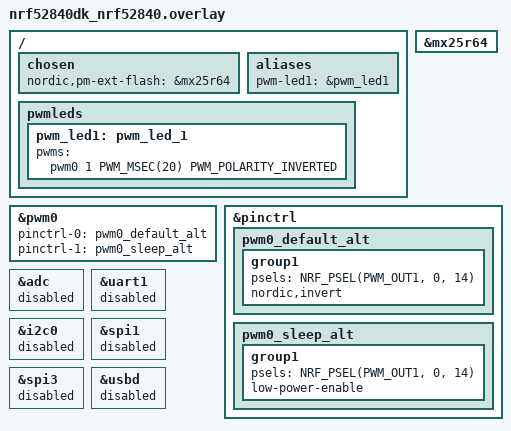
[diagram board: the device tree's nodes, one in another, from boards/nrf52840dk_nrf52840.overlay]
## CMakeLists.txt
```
#
#  Copyright (c) 2025 Nordic Semiconductor ASA
#
#  SPDX-License-Identifier: LicenseRef-Nordic-5-Clause
#


cmake_minimum_required(VERSION 3.20.0)

include(${CMAKE_CURRENT_LIST_DIR}/../../cmake/find_zephyr.cmake)

project(matter-closure)

# NORDIC SDK APP START

# Include all source files that are located in the Matter common directory.
include(${ZEPHYR_NCS_MATTER_MODULE_DIR}/cmake/sample.cmake)

ncs_get_zap_parent_dir(ZAP_PARENT_DIR)

target_include_directories(app PRIVATE
  src
  ${ZEPHYR_NCS_MATTER_MODULE_DIR}/subsys/util
  ${ZAP_PARENT_DIR}
)

target_sources(app PRIVATE
  src/app_task.cpp
  src/main.cpp
  src/closure_manager.cpp
  src/closure_control_endpoint.cpp
  src/garage_door_impl.cpp
  src/persistent_percent.cpp
)

ncs_configure_data_model()
# NORDIC SDK APP END
```

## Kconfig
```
#
# Copyright (c) 2025 Nordic Semiconductor
#
# SPDX-License-Identifier: LicenseRef-Nordic-5-Clause
#
mainmenu "Matter nRF Connect Closure Example Application"

# Sample configuration used for Thread networking
if OPENTHREAD

choice OPENTHREAD_NORDIC_LIBRARY_CONFIGURATION
	default OPENTHREAD_NORDIC_LIBRARY_FTD
endchoice

choice OPENTHREAD_DEVICE_TYPE
	default OPENTHREAD_FTD
endchoice

choice OPENTHREAD_IMPLEMENTATION
	default OPENTHREAD_SOURCES
endchoice

endif # OPENTHREAD

# Default triggers register OTA handler; this sample adds its own handler.
config MATTER_TEST_EVENT_TRIGGERS_MAX_TRIGGERS_DELEGATES
	default 3

config CHIP_WIFI
	default y if SHIELD_NRF7002EB2

source "$(ZEPHYR_CONNECTEDHOMEIP_MODULE_DIR)/config/nrfconnect/chip-module/Kconfig.features"
source "$(ZEPHYR_CONNECTEDHOMEIP_MODULE_DIR)/config/nrfconnect/chip-module/Kconfig.defaults"
source "Kconfig.zephyr"
```

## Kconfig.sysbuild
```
#
# Copyright (c) 2025 Nordic Semiconductor ASA
#
# SPDX-License-Identifier: LicenseRef-Nordic-5-Clause
#

config MATTER_ADD_ON
	default y

#### Radio core selection
config NRF_DEFAULT_IPC_RADIO
	default y

# Enable IEEE802.15.4 serialization to network core
# This config automatically pulls in the `overlay-802154.conf` in the ipc_radio image
config NETCORE_IPC_RADIO_IEEE802154
	default y if SOC_SERIES_NRF53

# Enable Bluetooth serialization to network core
# This config automatically pulls in the `overlay-bt_hci_ipc.conf` in the ipc_radio image
config NETCORE_IPC_RADIO_BT_HCI_IPC
	default y if SOC_SERIES_NRF53

#### Matter OTA
config MATTER_ADD_ON_OTA
	default n if BOARD_NRF7120DK_NRF7120_CPUAPP

#### Bootloader
choice BOOTLOADER
	default BOOTLOADER_MCUBOOT if !BOARD_NRF7120DK_NRF7120_CPUAPP
endchoice

if BOOTLOADER_MCUBOOT

#### DFU multi-image support
config DFU_MULTI_IMAGE_PACKAGE_BUILD
	default y

config DFU_MULTI_IMAGE_PACKAGE_APP
	default y

#### DFU network core configuration
if SOC_SERIES_NRF53

choice MCUBOOT_MODE
	default MCUBOOT_MODE_OVERWRITE_ONLY
endchoice

choice BOOT_SIGNATURE_TYPE
	default BOOT_SIGNATURE_TYPE_RSA
endchoice

config SECURE_BOOT_NETCORE
	default y

config NETCORE_APP_UPDATE
	default y

config DFU_MULTI_IMAGE_PACKAGE_NET
	default y

endif # SOC_SERIES_NRF53
endif # BOOTLOADER_MCUBOOT

#### Enable generating factory data
config MATTER_ADD_ON_FACTORY_DATA_GENERATE
	default y

source "share/sysbuild/Kconfig"
```

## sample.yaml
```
sample:
  description: Matter Closure sample
  name: Matter Closure
common:
  tags:
    - sysbuild
    - ci_samples_matter
tests:
  sample.matter.closure.debug:
    sysbuild: true
    build_only: true
    integration_platforms:
      - nrf5340dk/nrf5340/cpuapp
      - nrf54l15dk/nrf54l15/cpuapp
      - nrf54lm20dk/nrf54lm20b/cpuapp
      - nrf54lm20dk/nrf54lm20a/cpuapp
    platform_allow:
      - nrf5340dk/nrf5340/cpuapp
      - nrf54l15dk/nrf54l15/cpuapp
      - nrf54lm20dk/nrf54lm20b/cpuapp
      - nrf54lm20dk/nrf54lm20a/cpuapp
  sample.matter.closure.release:
    sysbuild: true
    build_only: true
    extra_args:
      - FILE_SUFFIX=release
    integration_platforms:
      - nrf5340dk/nrf5340/cpuapp
      - nrf54l15dk/nrf54l15/cpuapp
      - nrf54lm20dk/nrf54lm20b/cpuapp
      - nrf54lm20dk/nrf54lm20a/cpuapp
    platform_allow:
      - nrf5340dk/nrf5340/cpuapp
      - nrf54l15dk/nrf54l15/cpuapp
      - nrf54lm20dk/nrf54lm20b/cpuapp
      - nrf54lm20dk/nrf54lm20a/cpuapp
  sample.matter.closure.nrf7002eb2.debug:
    sysbuild: true
    build_only: true
    extra_args:
      - closure_SHIELD=nrf7002eb2
      - SB_CONFIG_WIFI_NRF70=y
    integration_platforms:
      - nrf54lm20dk/nrf54lm20b/cpuapp
      - nrf54lm20dk/nrf54lm20a/cpuapp
    platform_allow:
      - nrf54lm20dk/nrf54lm20b/cpuapp
      - nrf54lm20dk/nrf54lm20a/cpuapp
  sample.matter.closure.nrf7120.debug:
    sysbuild: true
    build_only: true
    extra_args:
      - CONFIG_CHIP_WIFI=y
      - CONFIG_WIFI_NRF71_PATCH=y
      - EXTRA_DTC_OVERLAY_FILE=${ZEPHYR_NRFXLIB_MODULE_DIR}/nrf71_wifi/bins/0.1.0/nrf7120_wifi_patch.dtsi
    integration_platforms:
      - nrf7120dk/nrf7120/cpuapp
    platform_allow:
      - nrf7120dk/nrf7120/cpuapp
  sample.matter.closure.nrf7002eb2.release:
    sysbuild: true
    build_only: true
    extra_args:
      - FILE_SUFFIX=release
      - SB_CONFIG_BOOTLOADER_MCUBOOT=y
      - closure_SHIELD=nrf7002eb2
      - SB_CONFIG_WIFI_NRF70=y
    integration_platforms:
      - nrf54lm20dk/nrf54lm20b/cpuapp
      - nrf54lm20dk/nrf54lm20a/cpuapp
    platform_allow:
      - nrf54lm20dk/nrf54lm20b/cpuapp
      - nrf54lm20dk/nrf54lm20a/cpuapp
  sample.matter.closure.nrf7120.release:
    sysbuild: true
    build_only: true
    extra_args:
      - FILE_SUFFIX=release
      - CONFIG_CHIP_WIFI=y
      - CONFIG_WIFI_NRF71_PATCH=y
      - EXTRA_DTC_OVERLAY_FILE=${ZEPHYR_NRFXLIB_MODULE_DIR}/nrf71_wifi/bins/0.1.0/nrf7120_wifi_patch.dtsi
    integration_platforms:
      - nrf7120dk/nrf7120/cpuapp
    platform_allow:
      - nrf7120dk/nrf7120/cpuapp
  sample.matter.closure.release.internal:
    sysbuild: true
    build_only: true
    extra_args:
      - FILE_SUFFIX=internal
      - closure_EXTRA_CONF_FILE=prj_release.conf
    integration_platforms:
      - nrf54lm20dk/nrf54lm20b/cpuapp
      - nrf54lm20dk/nrf54lm20a/cpuapp
    platform_allow:
      - nrf54lm20dk/nrf54lm20b/cpuapp
      - nrf54lm20dk/nrf54lm20a/cpuapp
```

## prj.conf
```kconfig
#
# Copyright (c) 2025 Nordic Semiconductor ASA
#
# SPDX-License-Identifier: LicenseRef-Nordic-5-Clause
#

# This sample uses Kconfig.defaults to set options common for all
# samples. This file should contain only options specific for this sample
# or overrides of default values.

# Enable CHIP
CONFIG_CHIP=y
CONFIG_CHIP_PROJECT_CONFIG="src/chip_project_config.h"
CONFIG_CHIP_DEVICE_PRODUCT_NAME="Matter Closure"

# Configure ZAP file name
CONFIG_MATTER_ZAP_FILE_PATH="${APPLICATION_CONFIG_DIR}/src/default_zap/closure.zap"

# 32768 == 0x8000 (example Product ID added temporaly,
# but it must be changed with proper PID from the list:
# https://github.com/project-chip/connectedhomeip/blob/482e6fd03196a6de45465a90003947ef4b86e0b1/docs/examples/discussion/PID_allocation_for_example_apps.md)
CONFIG_CHIP_DEVICE_PRODUCT_ID=32768
CONFIG_STD_CPP17=y

# Enable Matter pairing automatically on application start.
CONFIG_CHIP_ENABLE_PAIRING_AUTOSTART=y

# Enable Matter extended announcement and increase duration to 1 hour.
CONFIG_CHIP_BLE_EXT_ADVERTISING=y
CONFIG_CHIP_BLE_ADVERTISING_DURATION=60

# Add support for LEDs and buttons on Nordic development kits
CONFIG_DK_LIBRARY=y
CONFIG_PWM=y

# Bluetooth Low Energy configuration
CONFIG_BT_DEVICE_NAME="MatterClosure"

# Other settings
CONFIG_THREAD_NAME=y
CONFIG_MPU_STACK_GUARD=y
CONFIG_RESET_ON_FATAL_ERROR=n
CONFIG_CHIP_LIB_SHELL=y
CONFIG_MATTER_TEST_SHELL=y

# Disable NFC onboarding
CONFIG_CHIP_NFC_ONBOARDING_PAYLOAD=n

# Reduce application size
CONFIG_USE_SEGGER_RTT=n

# Enable Factory Data feature
CONFIG_CHIP_FACTORY_DATA=y
CONFIG_CHIP_FACTORY_DATA_BUILD=y

#Enable Persistent Storage
CONFIG_MATTER_PERSISTENT_STORAGE=y
```

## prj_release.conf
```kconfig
#
# Copyright (c) 2025 Nordic Semiconductor ASA
#
# SPDX-License-Identifier: LicenseRef-Nordic-5-Clause
#

# This sample uses Kconfig.defaults to set options common for all
# samples. This file should contain only options specific for this sample
# or overrides of default values.

# Enable CHIP
CONFIG_CHIP=y
CONFIG_CHIP_PROJECT_CONFIG="src/chip_project_config.h"
CONFIG_CHIP_DEVICE_PRODUCT_NAME="Matter Closure"

# Configure ZAP file name
CONFIG_MATTER_ZAP_FILE_PATH="${APPLICATION_CONFIG_DIR}/src/default_zap/closure.zap"

# 32768 == 0x8000 (example Product ID added temporaly,
# but it must be changed with proper PID from the list:
# https://github.com/project-chip/connectedhomeip/blob/482e6fd03196a6de45465a90003947ef4b86e0b1/docs/examples/discussion/PID_allocation_for_example_apps.md)
CONFIG_CHIP_DEVICE_PRODUCT_ID=32768
CONFIG_STD_CPP17=y

# Enable Matter pairing automatically on application start.
CONFIG_CHIP_ENABLE_PAIRING_AUTOSTART=y

# Enable Matter extended announcement and increase duration to 1 hour.
CONFIG_CHIP_BLE_EXT_ADVERTISING=y
CONFIG_CHIP_BLE_ADVERTISING_DURATION=60

# Add support for LEDs and buttons on Nordic development kits
CONFIG_DK_LIBRARY=y
CONFIG_PWM=y

# Bluetooth Low Energy configuration
CONFIG_BT_DEVICE_NAME="MatterClosure"

# Enable system reset on fatal error
CONFIG_RESET_ON_FATAL_ERROR=y

# Disable all debug features
CONFIG_USE_SEGGER_RTT=n
CONFIG_SHELL=n
CONFIG_OPENTHREAD_SHELL=n
CONFIG_CHIP_LIB_SHELL=n
CONFIG_CONSOLE=n
CONFIG_UART_CONSOLE=n
CONFIG_SERIAL=n
CONFIG_LOG=n
CONFIG_LOG_MODE_MINIMAL=n
CONFIG_ASSERT_VERBOSE=n
CONFIG_ASSERT_NO_FILE_INFO=y
CONFIG_PRINTK=n
CONFIG_PRINTK_SYNC=n
CONFIG_THREAD_NAME=n
CONFIG_BOOT_BANNER=n

# Disable NFC onboarding
CONFIG_CHIP_NFC_ONBOARDING_PAYLOAD=n

# Enable Factory Data feature
CONFIG_CHIP_FACTORY_DATA=y
CONFIG_CHIP_FACTORY_DATA_BUILD=y

# Enable Watchdog
CONFIG_MATTER_WATCHDOG=y

# Enable LTO to decrease the flash usage.
CONFIG_LTO=y
CONFIG_ISR_TABLES_LOCAL_DECLARATION=y

#Enable Persistent Storage
CONFIG_MATTER_PERSISTENT_STORAGE=y
```

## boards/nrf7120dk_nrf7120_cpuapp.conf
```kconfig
#
# Copyright (c) 2026 Nordic Semiconductor
#
# SPDX-License-Identifier: LicenseRef-Nordic-5-Clause
#

# Lower System ON idle current: see lib_nrf71_idle_power. Keep the
# default RAM_RETAIN_FULL tier; RAM_RETAIN_UNUSED_ONLY has been observed
# to cause issues on Wi-Fi builds.
CONFIG_NRF71_IDLE_POWER=y

# TODO: MCUboot is currently not supported on the nRF7120 DK.
CONFIG_CHIP_BOOTLOADER_NONE=y

# TODO: Currently MRAM does not support clearing factory data, so we can not
# migrate the DAC private key
CONFIG_CHIP_CRYPTO_PSA_MIGRATE_DAC_PRIV_KEY=n

# TODO: Enabling low-power mode unconditionally gives BLE more radio time,
# allowing the device to connect to Wi-Fi and send responses over BLE.
CONFIG_NRF_WIFI_LOW_POWER=y
```

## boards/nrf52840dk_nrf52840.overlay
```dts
/*
 * Copyright (c) 2025 Nordic Semiconductor ASA
 *
 * SPDX-License-Identifier: LicenseRef-Nordic-5-Clause
 */

#include <nrf52840_partitions.dtsi>

/ {
	chosen {
		nordic,pm-ext-flash = &mx25r64;
	};

	aliases {
		pwm-led1 = &pwm_led1;
	};

	pwmleds {
		pwm_led1: pwm_led_1 {
			pwms = <&pwm0 1 PWM_MSEC(20) PWM_POLARITY_INVERTED>;
		};
	};
};

&mx25r64 {
	status = "okay";
};

&pwm0 {
	pinctrl-0 = <&pwm0_default_alt>;
	pinctrl-1 = <&pwm0_sleep_alt>;
	pinctrl-names = "default", "sleep";
};

&pinctrl {
	pwm0_default_alt: pwm0_default_alt {
		group1 {
			psels = <NRF_PSEL(PWM_OUT1, 0, 14)>;
			nordic,invert;
		};
	};

	pwm0_sleep_alt: pwm0_sleep_alt {
		group1 {
			psels = <NRF_PSEL(PWM_OUT1, 0, 14)>;
			low-power-enable;
		};
	};
};

/* Disable unused peripherals to reduce power consumption */
&adc {
	status = "disabled";
};

&uart1 {
	status = "disabled";
};

&i2c0 {
	status = "disabled";
};

&spi1 {
	status = "disabled";
};

&spi3 {
	status = "disabled";
};

&usbd {
	status = "disabled";
};
```

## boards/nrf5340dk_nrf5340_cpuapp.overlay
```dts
/*
 * Copyright (c) 2025 Nordic Semiconductor ASA
 *
 * SPDX-License-Identifier: LicenseRef-Nordic-5-Clause
 */

#include <nrf5340_cpuapp_partitions.dtsi>
#include <zephyr/dt-bindings/ipc_service/static_vrings.h>

/ {
	chosen {
		nordic,pm-ext-flash = &mx25r64;
	};

	aliases {
		pwm-led1 = &pwm_led1;
	};

	pwmleds {
		compatible = "pwm-leds";

		pwm_led1: pwm_led_1 {
			pwms = <&pwm0 1 PWM_MSEC(20) PWM_POLARITY_INVERTED>;
		};
	};
};

/* Set IPC thread priority to the highest value to not collide with other threads. */
&ipc0 {
	zephyr,priority = <0 PRIO_COOP>;
};

&mx25r64 {
	status = "okay";
};

&pwm0 {
	pinctrl-0 = <&pwm0_default_alt>;
	pinctrl-1 = <&pwm0_sleep_alt>;
	pinctrl-names = "default", "sleep";
};

&pinctrl {
	pwm0_default_alt: pwm0_default_alt {
		group1 {
			psels = <NRF_PSEL(PWM_OUT1, 0, 29)>;
			nordic,invert;
		};
	};

	pwm0_sleep_alt: pwm0_sleep_alt {
		group1 {
			psels = <NRF_PSEL(PWM_OUT1, 0, 29)>;
			low-power-enable;
		};
	};
};

/* Disable unused peripherals to reduce power consumption */
&adc {
	status = "disabled";
};

&i2c1 {
	status = "disabled";
};

&spi2 {
	status = "disabled";
};

&usbd {
	status = "disabled";
};
```

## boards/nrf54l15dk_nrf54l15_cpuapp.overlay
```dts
/*
 * Copyright (c) 2025 Nordic Semiconductor ASA
 *
 * SPDX-License-Identifier: LicenseRef-Nordic-5-Clause
 */

#include <nrf54l15_cpuapp_partitions.dtsi>

/ {
	chosen {
		nordic,pm-ext-flash = &mx25r64;
	};

	aliases {
		/* Configure PWM module for led1 (LED2 on the board) */
		pwm-led1 = &pwm_led1;

		/* Use watchdog wdt31 as the application watchdog */
		watchdog0 = &wdt31;
	};

	pwmleds {
		compatible = "pwm-leds";

		pwm_led1: pwm_led_1 {
			pwms = <&pwm20 1 PWM_MSEC(20) PWM_POLARITY_NORMAL>;
		};
	};
};

&mx25r64 {
	status = "okay";
};

&pwm20 {
	status = "okay";
	pinctrl-0 = <&pwm_default>;
	pinctrl-1 = <&pwm_sleep>;
	pinctrl-names = "default", "sleep";
};

&pinctrl {
	pwm_default: pwm_default {
		group1 {
			psels = <NRF_PSEL(PWM_OUT1, 1, 10)>, <NRF_PSEL(PWM_OUT2, 1, 14)>;
		};
	};

	pwm_sleep: pwm_sleep {
		group1 {
			psels = <NRF_PSEL(PWM_OUT1, 1, 10)>, <NRF_PSEL(PWM_OUT2, 1, 14)>;
			low-power-enable;
		};
	};
};

&wdt31 {
	status = "okay";
};
```

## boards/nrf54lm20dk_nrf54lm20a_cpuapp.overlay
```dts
/*
 * Copyright (c) 2025 Nordic Semiconductor ASA
 *
 * SPDX-License-Identifier: LicenseRef-Nordic-5-Clause
 */

#include <nrf54lm20_cpuapp_partitions.dtsi>

/ {
	chosen {
		nordic,pm-ext-flash = &mx25r64;
	};

	aliases {
		/* Use watchdog wdt31 as the application watchdog */
		watchdog0 = &wdt31;
		pwm-led1 = &pwm_led1;
	};

	pwmleds {
		compatible = "pwm-leds";

		pwm_led1: pwm_led_1 {
			pwms = <&pwm20 1 PWM_MSEC(20) PWM_POLARITY_NORMAL>;
		};
	};
};

&pwm20 {
	status = "okay";
	pinctrl-0 = <&pwm_default>;
	pinctrl-1 = <&pwm_sleep>;
	pinctrl-names = "default", "sleep";
};

&pinctrl {
	pwm_default: pwm_default {
		group1 {
			psels = <NRF_PSEL(PWM_OUT1, 1, 25)>;
		};
	};

	pwm_sleep: pwm_sleep {
		group1 {
			psels = <NRF_PSEL(PWM_OUT1, 1, 25)>;
			low-power-enable;
		};
	};
};

&mx25r64 {
	status = "okay";
};

&wdt31 {
	status = "okay";
};
```

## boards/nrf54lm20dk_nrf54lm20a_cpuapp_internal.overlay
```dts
/*
 * Copyright (c) 2025 Nordic Semiconductor ASA
 *
 * SPDX-License-Identifier: LicenseRef-Nordic-5-Clause
 */

#include <nrf54lm20_cpuapp_internal_partitions.dtsi>

/ {
	aliases {
		/* Use watchdog wdt31 as the application watchdog */
		watchdog0 = &wdt31;
		pwm-led1 = &pwm_led1;
	};

	pwmleds {
		compatible = "pwm-leds";

		pwm_led1: pwm_led_1 {
			pwms = <&pwm20 1 PWM_MSEC(20) PWM_POLARITY_NORMAL>;
		};
	};
};

&pwm20 {
	status = "okay";
	pinctrl-0 = <&pwm_default>;
	pinctrl-1 = <&pwm_sleep>;
	pinctrl-names = "default", "sleep";
};

&pinctrl {
	pwm_default: pwm_default {
		group1 {
			psels = <NRF_PSEL(PWM_OUT1, 1, 25)>;
		};
	};

	pwm_sleep: pwm_sleep {
		group1 {
			psels = <NRF_PSEL(PWM_OUT1, 1, 25)>;
			low-power-enable;
		};
	};
};

&wdt31 {
	status = "okay";
};
```

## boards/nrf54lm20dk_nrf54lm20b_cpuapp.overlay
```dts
/*
 * Copyright (c) 2026 Nordic Semiconductor ASA
 *
 * SPDX-License-Identifier: LicenseRef-Nordic-5-Clause
 */

#include <nrf54lm20_cpuapp_partitions.dtsi>

/ {
	chosen {
		nordic,pm-ext-flash = &mx25r64;
	};

	aliases {
		/* Use watchdog wdt31 as the application watchdog */
		watchdog0 = &wdt31;
		pwm-led1 = &pwm_led1;
	};

	pwmleds {
		compatible = "pwm-leds";

		pwm_led1: pwm_led_1 {
			pwms = <&pwm20 1 PWM_MSEC(20) PWM_POLARITY_NORMAL>;
		};
	};
};

&pwm20 {
	status = "okay";
	pinctrl-0 = <&pwm_default>;
	pinctrl-1 = <&pwm_sleep>;
	pinctrl-names = "default", "sleep";
};

&pinctrl {
	pwm_default: pwm_default {
		group1 {
			psels = <NRF_PSEL(PWM_OUT1, 1, 25)>;
		};
	};

	pwm_sleep: pwm_sleep {
		group1 {
			psels = <NRF_PSEL(PWM_OUT1, 1, 25)>;
			low-power-enable;
		};
	};
};

&mx25r64 {
	status = "okay";
};

&wdt31 {
	status = "okay";
};
```

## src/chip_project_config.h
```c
/*
 * Copyright (c) 2025 Nordic Semiconductor ASA
 *
 * SPDX-License-Identifier: LicenseRef-Nordic-5-Clause
 */

/**
 *    @file
 *          Example project configuration file for CHIP.
 *
 *          This is a place to put application or project-specific overrides
 *          to the default configuration values for general CHIP features.
 *
 */

#pragma once

#include "../../../subsys/app/chip_project_config_native_sim.h"
```

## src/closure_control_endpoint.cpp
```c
/*
 * Copyright (c) 2025 Nordic Semiconductor ASA
 *
 * SPDX-License-Identifier: LicenseRef-Nordic-5-Clause
 */

#include "closure_control_endpoint.h"
#include "closure_manager.h"
#include <app-common/zap-generated/attributes/Accessors.h>
#include <app-common/zap-generated/cluster-enums.h>
#include <app-common/zap-generated/cluster-objects.h>
#include <platform/CHIPDeviceLayer.h>
#include <protocols/interaction_model/StatusCode.h>
#include <zephyr/logging/log.h>

#ifdef CONFIG_MATTER_TEST_EVENT_TRIGGERS
#include <event_triggers/event_triggers.h>
#endif

LOG_MODULE_DECLARE(closure_cntrl, CONFIG_CHIP_APP_LOG_LEVEL);

using namespace chip;
using namespace chip::app::Clusters::ClosureControl;

using Status = chip::Protocols::InteractionModel::Status;
using TargetPositionEnum = chip::app::Clusters::ClosureControl::TargetPositionEnum;
using ThreeLevelAutoEnum = chip::app::Clusters::Globals::ThreeLevelAutoEnum;
using OptionalAttributeEnum = chip::app::Clusters::ClosureControl::OptionalAttributeEnum;
namespace
{

constexpr ElapsedS kDefaultCountdownTime = 30;

enum class ClosureControlTestEventTrigger : Nrf::Matter::TestEventTrigger::EventTriggerId {
	kMainStateIsError = 0x0104000000000000,
	kMainStateIsProtected = 0x0104000000000001,
	kMainStateIsDisengaged = 0x0104000000000002,
	kMainStateIsSetupRequired = 0x0104000000000003,
	kClearEvent = 0x0104000000000004,
};

} /* namespace */

Status ClosureControlDelegate::HandleCalibrateCommand()
{
	if (mManager == nullptr) {
		LOG_ERR("No manager bound to ClosureControlDelegate");
		return Status::Failure;
	}
	return mManager->OnCalibrateCommand();
}

Status ClosureControlDelegate::HandleMoveToCommand(const chip::Optional<TargetPositionEnum> &position,
						   const chip::Optional<bool> &latch,
						   const chip::Optional<ThreeLevelAutoEnum> &speed)
{
	if (mManager == nullptr) {
		LOG_ERR("No manager bound to ClosureControlDelegate");
		return Status::Failure;
	}
	return mManager->OnMoveToCommand(position, latch, speed);
}

Status ClosureControlDelegate::HandleStopCommand()
{
	if (mManager == nullptr) {
		LOG_ERR("No manager bound to ClosureControlDelegate");
		return Status::Failure;
	}
	return mManager->OnStopCommand();
}

bool ClosureControlDelegate::IsReadyToMove()
{
	/* This function should return true if the closure is ready to move.
	   For now, we will return true. */
	return true;
}

ElapsedS ClosureControlDelegate::GetCalibrationCountdownTime()
{
	/* This function should return the calibration countdown time.
	   For now, we will return kDefaultCountdownTime. */
	return kDefaultCountdownTime;
}

ElapsedS ClosureControlDelegate::GetMovingCountdownTime()
{
	return mManager->GetMoveCountdownTime();
}

ElapsedS ClosureControlDelegate::GetWaitingForMotionCountdownTime()
{
	/* This function should return the waiting for motion countdown time.
	   For now, we will return kDefaultCountdownTime. */
	return kDefaultCountdownTime;
}

CHIP_ERROR ClosureControlEndpoint::Init()
{
	ClusterConformance conformance;
	conformance.FeatureMap().Set(Feature::kPositioning).Set(Feature::kSpeed).Set(Feature::kVentilation);
	conformance.OptionalAttributes().Set(OptionalAttributeEnum::kCountdownTime);

	ClusterInitParameters initParams;

	ReturnErrorOnFailure(mLogic.Init(conformance, initParams));
	ReturnErrorOnFailure(mInterface.Init());

#ifdef CONFIG_MATTER_TEST_EVENT_TRIGGERS
	ReturnErrorOnFailure(Nrf::Matter::TestEventTrigger::Instance().RegisterTestEventTriggerHandler(&mDelegate));
#endif

	return CHIP_NO_ERROR;
}

CHIP_ERROR
ClosureControlEndpoint::WriteAllAttributes(const MainStateEnum &mainState,
					   const GenericOverallCurrentState &currentState,
					   const chip::app::DataModel::Nullable<GenericOverallTargetState> &targetState)
{
	chip::DeviceLayer::StackLock lock;
	ReturnErrorOnFailure(mLogic.SetMainState(mainState));
	ReturnErrorOnFailure(mLogic.SetOverallCurrentState(currentState));
	ReturnErrorOnFailure(mLogic.SetCountdownTimeFromDelegate(mDelegate.GetMovingCountdownTime()));

	if (!targetState.IsNull()) {
		ReturnErrorOnFailure(mLogic.SetOverallTargetState(targetState.Value()));
	}

	return CHIP_NO_ERROR;
}

CHIP_ERROR
ClosureControlEndpoint::OnMovementStopped(const MainStateEnum &mainState,
					  const GenericOverallCurrentState &currentState,
					  const chip::app::DataModel::Nullable<GenericOverallTargetState> &targetState)
{
	ReturnErrorOnFailure(WriteAllAttributes(mainState, currentState, targetState));
	ReturnErrorOnFailure(GetLogic().GenerateMovementCompletedEvent());
	return CHIP_NO_ERROR;
}

CHIP_ERROR
ClosureControlEndpoint::OnMovementUpdate(const MainStateEnum &mainState, const GenericOverallCurrentState &currentState,
					 const chip::app::DataModel::Nullable<GenericOverallTargetState> &targetState)
{
	return WriteAllAttributes(mainState, currentState, targetState);
}

CHIP_ERROR ClosureControlDelegate::HandleEventTrigger(uint64_t eventTrigger)
{
	eventTrigger = clearEndpointInEventTrigger(eventTrigger);

	auto trigger = static_cast<ClosureControlTestEventTrigger>(eventTrigger);
	auto logic = GetLogic();

	switch (trigger) {
	case ClosureControlTestEventTrigger::kMainStateIsError:
		ReturnErrorOnFailure(logic->SetMainState(MainStateEnum::kError));
		ReturnErrorOnFailure(logic->AddErrorToCurrentErrorList(ClosureErrorEnum::kBlockedBySensor));
		break;
	case ClosureControlTestEventTrigger::kMainStateIsProtected:
		ReturnErrorOnFailure(logic->SetMainState(MainStateEnum::kProtected));
		break;
	case ClosureControlTestEventTrigger::kMainStateIsDisengaged:
		ReturnErrorOnFailure(logic->SetMainState(MainStateEnum::kDisengaged));
		break;
	case ClosureControlTestEventTrigger::kMainStateIsSetupRequired:
		ReturnErrorOnFailure(logic->SetMainState(MainStateEnum::kSetupRequired));
		break;
	case ClosureControlTestEventTrigger::kClearEvent:
		ReturnErrorOnFailure(logic->SetMainState(MainStateEnum::kStopped));
		logic->ClearCurrentErrorList();
		break;
	default:
		return CHIP_ERROR_INVALID_ARGUMENT;
	}
	return CHIP_NO_ERROR;
}
```
